# SF32LB58x register map
File version: 1.0
CPU: CM33 r0p1, little endian, MPU, FPU, 3 interrupt priority bits
Registers are 32-bit, read-write, reset 0x0 unless marked. A register's access mark holds for its fields unless they carry their own. Offsets are from the block's base; [hi:lo] are bit positions.

## LPSYS_RCC
Base 0x50000000
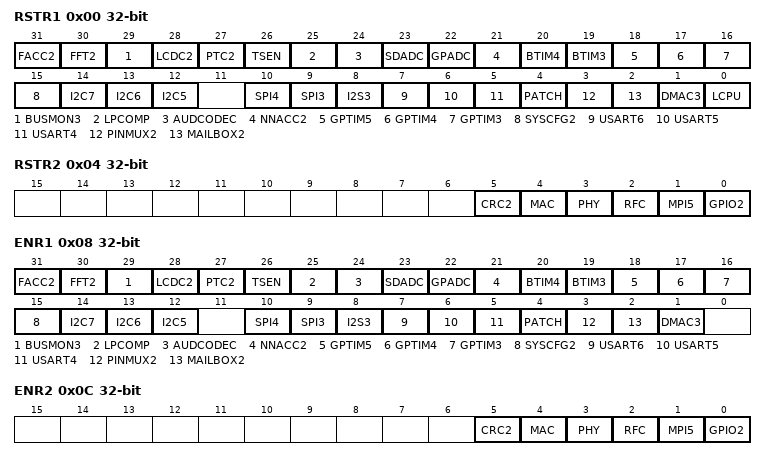
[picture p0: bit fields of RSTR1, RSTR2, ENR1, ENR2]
0x00 RSTR1 — Reset Register
  [31] FACC2 — 0 - no reset; 1 - reset
  [30] FFT2 — 0 - no reset; 1 - reset
  [29] BUSMON3 — 0 - no reset; 1 - reset
  [28] LCDC2 — 0 - no reset; 1 - reset
  [27] PTC2 — 0 - no reset; 1 - reset
  [26] TSEN — 0 - no reset; 1 - reset
  [25] LPCOMP — 0 - no reset; 1 - reset
  [24] AUDCODEC — 0 - no reset; 1 - reset
  [23] SDADC — 0 - no reset; 1 - reset
  [22] GPADC — 0 - no reset; 1 - reset
  [21] NNACC2 — 0 - no reset; 1 - reset
  [20] BTIM4 — 0 - no reset; 1 - reset
  [19] BTIM3 — 0 - no reset; 1 - reset
  [18] GPTIM5 — 0 - no reset; 1 - reset
  [17] GPTIM4 — 0 - no reset; 1 - reset
  [16] GPTIM3 — 0 - no reset; 1 - reset
  [15] SYSCFG2 — 0 - no reset; 1 - reset
  [14] I2C7 — 0 - no reset; 1 - reset
  [13] I2C6 — 0 - no reset; 1 - reset
  [12] I2C5 — 0 - no reset; 1 - reset
  [10] SPI4 — 0 - no reset; 1 - reset
  [9] SPI3 — 0 - no reset; 1 - reset
  [8] I2S3 — 0 - no reset; 1 - reset
  [7] USART6 — 0 - no reset; 1 - reset
  [6] USART5 — 0 - no reset; 1 - reset
  [5] USART4 — 0 - no reset; 1 - reset
  [4] PATCH — 0 - no reset; 1 - reset
  [3] PINMUX2 — 0 - no reset; 1 - reset
  [2] MAILBOX2 — 0 - no reset; 1 - reset
  [1] DMAC3 — 0 - no reset; 1 - reset
  [0] LCPU — 0 - no reset; 1 - reset
0x04 RSTR2 — Reset Register
  [5] CRC2 — 0 - no reset; 1 - reset
  [4] MAC — 0 - no reset; 1 - reset
  [3] PHY — 0 - no reset; 1 - reset
  [2] RFC — 0 - no reset; 1 - reset
  [1] MPI5 — 0 - no reset; 1 - reset
  [0] GPIO2 — 0 - no reset; 1 - reset
0x08 ENR1 — Enable Register
  [31] FACC2 — 0 - disabled; 1 - enabled
  [30] FFT2 — 0 - disabled; 1 - enabled
  [29] BUSMON3 — 0 - disabled; 1 - enabled
  [28] LCDC2 — 0 - disabled; 1 - enabled
  [27] PTC2 — 0 - disabled; 1 - enabled
  [26] TSEN — 0 - disabled; 1 - enabled
  [25] LPCOMP — 0 - disabled; 1 - enabled
  [24] AUDCODEC — 0 - disabled; 1 - enabled
  [23] SDADC — 0 - disabled; 1 - enabled
  [22] GPADC — 0 - disabled; 1 - enabled
  [21] NNACC2 — 0 - disabled; 1 - enabled
  [20] BTIM4 — 0 - disabled; 1 - enabled
  [19] BTIM3 — 0 - disabled; 1 - enabled
  [18] GPTIM5 — 0 - disabled; 1 - enabled
  [17] GPTIM4 — 0 - disabled; 1 - enabled
  [16] GPTIM3 — 0 - disabled; 1 - enabled
  [15] SYSCFG2 — 0 - disabled; 1 - enabled
  [14] I2C7 — 0 - disabled; 1 - enabled
  [13] I2C6 — 0 - disabled; 1 - enabled
  [12] I2C5 — 0 - disabled; 1 - enabled
  [10] SPI4 — 0 - disabled; 1 - enabled
  [9] SPI3 — 0 - disabled; 1 - enabled
  [8] I2S3 — 0 - disabled; 1 - enabled
  [7] USART6 — 0 - disabled; 1 - enabled
  [6] USART5 — 0 - disabled; 1 - enabled
  [5] USART4 — 0 - disabled; 1 - enabled
  [4] PATCH — 0 - disabled; 1 - enabled
  [3] PINMUX2 — 0 - disabled; 1 - enabled
  [2] MAILBOX2 — 0 - disabled; 1 - enabled
  [1] DMAC3 — 0 - disabled; 1 - enabled
0x0C ENR2 — Reset Register
  [5] CRC2 — 0 - disabled; 1 - enabled
  [4] MAC — 0 - disabled; 1 - enabled
  [3] PHY — 0 - disabled; 1 - enabled
  [2] RFC — 0 - disabled; 1 - enabled
  [1] MPI5 — 0 - disabled; 1 - enabled
  [0] GPIO2 — 0 - disabled; 1 - enabled
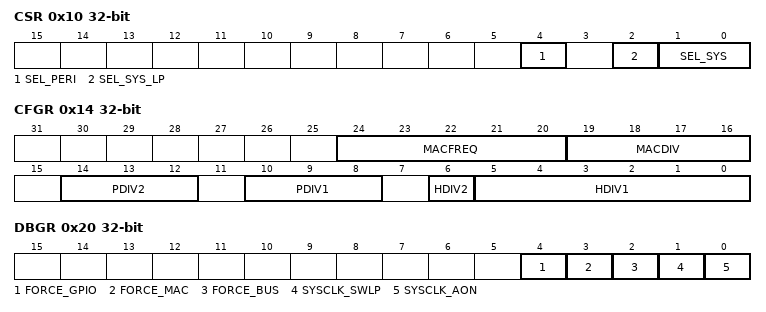
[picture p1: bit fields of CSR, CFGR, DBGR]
0x10 CSR — Clock Select Register
  [4] SEL_PERI — select clk_peri source used by USART/SPI/I2C 0 - hrc48; 1 - hxt48
  [2] SEL_SYS_LP — select clk_sys source 0 - selected by SEL_SYS; 1 - clk_lp
  [1:0] SEL_SYS — select clk_sys source 0 - hrc48; 1 - hxt48; 2 - dbl96; 3 - reserved
0x14 CFGR — Clock Configuration Register
  [24:20] MACFREQ — clock frequency of MAC clock
  [19:16] MACDIV — MAC clock divider MACCLK = hclk / MACDIV
  [14:12] PDIV2 — pclk2 = hclk / (2^PDIV2), by default divided by 32
  [10:8] PDIV1 — pclk = hclk / (2^PDIV1), by default divided by 2
  [6] HDIV2 — should set to 0 if hclk frequency no higher than 24MHz should set to 1 if hclk frequency higher than 24MHz
  [5:0] HDIV1 — hclk = clk_sys / HDIV1 if HDIV1=0, hclk = clk_sys
0x20 DBGR — Debug Register
  [4] FORCE_GPIO — for debug only
  [3] FORCE_MAC — for debug only
  [2] FORCE_BUS — for debug only
  [1] SYSCLK_SWLP — for debug only
  [0] SYSCLK_AON — for debug only
